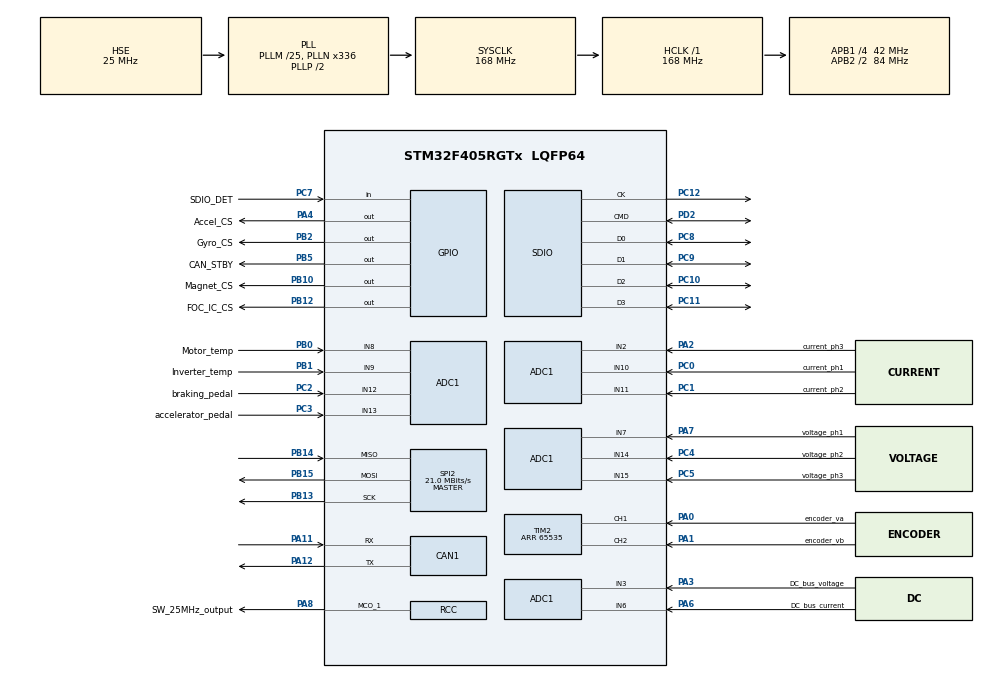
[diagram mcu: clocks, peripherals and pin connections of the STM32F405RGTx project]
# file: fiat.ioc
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ADC1.Channel-10\#ChannelRegularConversion=ADC_CHANNEL_9
ADC1.Channel-11\#ChannelRegularConversion=ADC_CHANNEL_6
ADC1.Channel-12\#ChannelRegularConversion=ADC_CHANNEL_3
ADC1.Channel-13\#ChannelRegularConversion=ADC_CHANNEL_12
ADC1.Channel-14\#ChannelRegularConversion=ADC_CHANNEL_13
ADC1.Channel-3\#ChannelRegularConversion=ADC_CHANNEL_10
ADC1.Channel-4\#ChannelRegularConversion=ADC_CHANNEL_11
ADC1.Channel-5\#ChannelRegularConversion=ADC_CHANNEL_2
ADC1.Channel-6\#ChannelRegularConversion=ADC_CHANNEL_7
ADC1.Channel-7\#ChannelRegularConversion=ADC_CHANNEL_14
ADC1.Channel-8\#ChannelRegularConversion=ADC_CHANNEL_15
ADC1.Channel-9\#ChannelRegularConversion=ADC_CHANNEL_8
ADC1.ContinuousConvMode=ENABLE
ADC1.DMAContinuousRequests=ENABLE
ADC1.NbrOfConversion=12
ADC1.NbrOfConversionFlag=1
ADC1.Rank-10\#ChannelRegularConversion=8
ADC1.Rank-11\#ChannelRegularConversion=9
ADC1.Rank-12\#ChannelRegularConversion=10
ADC1.Rank-13\#ChannelRegularConversion=11
ADC1.Rank-14\#ChannelRegularConversion=12
ADC1.Rank-3\#ChannelRegularConversion=1
ADC1.Rank-4\#ChannelRegularConversion=2
ADC1.Rank-5\#ChannelRegularConversion=3
ADC1.Rank-6\#ChannelRegularConversion=4
ADC1.Rank-7\#ChannelRegularConversion=5
ADC1.Rank-8\#ChannelRegularConversion=6
ADC1.Rank-9\#ChannelRegularConversion=7
ADC1.SamplingTime-10\#ChannelRegularConversion=ADC_SAMPLETIME_3CYCLES
ADC1.SamplingTime-11\#ChannelRegularConversion=ADC_SAMPLETIME_3CYCLES
ADC1.SamplingTime-12\#ChannelRegularConversion=ADC_SAMPLETIME_3CYCLES
ADC1.SamplingTime-13\#ChannelRegularConversion=ADC_SAMPLETIME_3CYCLES
ADC1.SamplingTime-14\#ChannelRegularConversion=ADC_SAMPLETIME_3CYCLES
ADC1.SamplingTime-3\#ChannelRegularConversion=ADC_SAMPLETIME_3CYCLES
ADC1.SamplingTime-4\#ChannelRegularConversion=ADC_SAMPLETIME_3CYCLES
ADC1.SamplingTime-5\#ChannelRegularConversion=ADC_SAMPLETIME_3CYCLES
ADC1.SamplingTime-6\#ChannelRegularConversion=ADC_SAMPLETIME_3CYCLES
ADC1.SamplingTime-7\#ChannelRegularConversion=ADC_SAMPLETIME_3CYCLES
ADC1.SamplingTime-8\#ChannelRegularConversion=ADC_SAMPLETIME_3CYCLES
ADC1.SamplingTime-9\#ChannelRegularConversion=ADC_SAMPLETIME_3CYCLES
ADC1.ScanConvMode=ENABLE
ADC1.master=1
CAN1.CalculateTimeQuantum=380.95238095238096
Dma.ADC1.0.Direction=DMA_PERIPH_TO_MEMORY
Dma.ADC1.0.FIFOMode=DMA_FIFOMODE_DISABLE
Dma.ADC1.0.Instance=DMA2_Stream0
Dma.ADC1.0.MemDataAlignment=DMA_MDATAALIGN_WORD
Dma.ADC1.0.MemInc=DMA_MINC_ENABLE
Dma.ADC1.0.Mode=DMA_CIRCULAR
Dma.ADC1.0.PeriphDataAlignment=DMA_PDATAALIGN_WORD
Dma.ADC1.0.PeriphInc=DMA_PINC_DISABLE
Dma.ADC1.0.Priority=DMA_PRIORITY_LOW
Dma.Request0=ADC1
FATFS.BSP.number=1
FATFS._FS_NORTC=0
FATFS0.BSP.STBoard=false
FATFS0.BSP.api=Unknown
FATFS0.BSP.i2caddr=0
FATFS0.BSP.instance=PC7
FATFS0.BSP.ip=GPIO
FATFS0.BSP.mode=Input
FATFS0.BSP.name=Detect_SDIO
FATFS0.BSP.solution=PC7
Mcu.Family=STM32F4
Mcu.Name=STM32F405RGTx
Mcu.Package=LQFP64
NVIC.DMA2_Stream0_IRQn=true\:0\:0\:false\:false\:true\:false\:true
NVIC.PriorityGroup=NVIC_PRIORITYGROUP_4
NVIC.RTC_Alarm_IRQn=true\:0\:0\:false\:false\:true\:true\:true
NVIC.TIM6_DAC_IRQn=true\:0\:0\:false\:false\:true\:true\:true
PA0-WKUP.GPIO_Label=encoder_va
PA0-WKUP.GPIO_PuPd=GPIO_PULLUP
PA0-WKUP.Signal=S_TIM2_CH1_ETR
PA1.GPIO_Label=encoder_vb
PA1.GPIO_PuPd=GPIO_PULLUP
PA1.Signal=S_TIM2_CH2
PA11.Mode=Master
PA11.Signal=CAN1_RX
PA12.Mode=Master
PA12.Signal=CAN1_TX
PA13.Mode=Serial_Wire
PA13.Signal=SYS_JTMS-SWDIO
PA14.Mode=Serial_Wire
PA14.Signal=SYS_JTCK-SWCLK
PA2.GPIO_Label=current_ph3
PA2.Signal=ADCx_IN2
PA3.GPIO_Label=DC_bus_voltage
PA3.Signal=ADCx_IN3
PA4.GPIO_Label=Accel_CS
PA4.Signal=GPIO_Output
PA6.GPIO_Label=DC_bus_current
PA6.Signal=ADCx_IN6
PA7.GPIO_Label=voltage_ph1
PA7.Signal=ADCx_IN7
PA8.GPIO_Label=SW_25MHz_output
PA8.Mode=Clock-out-1
PA8.Signal=RCC_MCO_1
PB0.GPIO_Label=Motor_temp
PB0.Signal=ADCx_IN8
PB1.GPIO_Label=Inverter_temp
PB1.Signal=ADCx_IN9
PB10.GPIO_Label=Magnet_CS
PB10.Signal=GPIO_Output
PB12.GPIO_Label=FOC_IC_CS
PB12.Signal=GPIO_Output
PB13.Mode=Full_Duplex_Master
PB13.Signal=SPI2_SCK
PB14.Mode=Full_Duplex_Master
PB14.Signal=SPI2_MISO
PB15.Mode=Full_Duplex_Master
PB15.Signal=SPI2_MOSI
PB2.GPIO_Label=Gyro_CS
PB2.Signal=GPIO_Output
PB5.GPIO_Label=CAN_STBY
PB5.Signal=GPIO_Output
PC0.GPIO_Label=current_ph1
PC0.Signal=ADCx_IN10
PC1.GPIO_Label=current_ph2
PC1.Signal=ADCx_IN11
PC10.Mode=SD_4_bits_Wide_bus
PC10.Signal=SDIO_D2
PC11.Mode=SD_4_bits_Wide_bus
PC11.Signal=SDIO_D3
PC12.Mode=SD_4_bits_Wide_bus
PC12.Signal=SDIO_CK
PC14-OSC32_IN.Mode=LSE-External-Oscillator
PC14-OSC32_IN.Signal=RCC_OSC32_IN
PC15-OSC32_OUT.Mode=LSE-External-Oscillator
PC15-OSC32_OUT.Signal=RCC_OSC32_OUT
PC2.GPIO_Label=braking_pedal
PC2.Signal=ADCx_IN12
PC3.GPIO_Label=accelerator_pedal
PC3.Signal=ADCx_IN13
PC4.GPIO_Label=voltage_ph2
PC4.Signal=ADCx_IN14
PC5.GPIO_Label=voltage_ph3
PC5.Signal=ADCx_IN15
PC7.GPIO_Label=SDIO_DET
PC7.Signal=GPIO_Input
PC8.Mode=SD_4_bits_Wide_bus
PC8.Signal=SDIO_D0
PC9.Mode=SD_4_bits_Wide_bus
PC9.Signal=SDIO_D1
PD2.Mode=SD_4_bits_Wide_bus
PD2.Signal=SDIO_CMD
PH0-OSC_IN.Mode=HSE-External-Oscillator
PH0-OSC_IN.Signal=RCC_OSC_IN
PH1-OSC_OUT.Mode=HSE-External-Oscillator
PH1-OSC_OUT.Signal=RCC_OSC_OUT
ProjectManager.HeapSize=0x200
ProjectManager.StackSize=0x400
ProjectManager.TargetToolchain=STM32CubeIDE
RCC.48MHZClocksFreq_Value=48000000
RCC.AHBFreq_Value=168000000
RCC.APB1CLKDivider=RCC_HCLK_DIV4
RCC.APB1Freq_Value=42000000
RCC.APB1TimFreq_Value=84000000
RCC.APB2CLKDivider=RCC_HCLK_DIV2
RCC.APB2Freq_Value=84000000
RCC.APB2TimFreq_Value=168000000
RCC.CortexFreq_Value=168000000
RCC.HCLKFreq_Value=168000000
RCC.HSE_VALUE=25000000
RCC.HSI_VALUE=16000000
RCC.PLLM=25
RCC.PLLN=336
RCC.PLLQ=7
RCC.PLLSourceVirtual=RCC_PLLSOURCE_HSE
RCC.RCC_MCO1Source=RCC_MCO1SOURCE_HSE
RCC.RCC_MCODiv1=RCC_MCODIV_2
RCC.RCC_RTC_Clock_Source=RCC_RTCCLKSOURCE_LSE
RCC.RCC_RTC_Clock_SourceVirtual=RCC_RTCCLKSOURCE_LSE
RCC.SYSCLKFreq_VALUE=168000000
RCC.SYSCLKSource=RCC_SYSCLKSOURCE_PLLCLK
RCC.VCOOutputFreq_Value=336000000
RTC.Alarm=RTC_ALARM_A
RTC.AlarmMaskDateWeekDay=RTC_ALARMMASK_DATEWEEKDAY
RTC.AlarmMaskHours=RTC_ALARMMASK_HOURS
RTC.AlarmMaskMinutes=RTC_ALARMMASK_MINUTES
RTC.AlarmMaskSeconds=RTC_ALARMMASK_SECONDS
RTC.AlarmSubSecondMask=RTC_ALARMSUBSECONDMASK_ALL
RTC.Date=9
RTC.Hours=16
RTC.Hours_A=0
RTC.Minutes_A=0
RTC.Seconds_A=0
RTC.SubSeconds_A=0
RTC.WeekDay=RTC_WEEKDAY_THURSDAY
RTC.Year=20
SH.ADCx_IN10.0=ADC1_IN10,IN10
SH.ADCx_IN11.0=ADC1_IN11,IN11
SH.ADCx_IN12.0=ADC1_IN12,IN12
SH.ADCx_IN13.0=ADC1_IN13,IN13
SH.ADCx_IN14.0=ADC1_IN14,IN14
SH.ADCx_IN15.0=ADC1_IN15,IN15
SH.ADCx_IN2.0=ADC1_IN2,IN2
SH.ADCx_IN3.0=ADC1_IN3,IN3
SH.ADCx_IN6.0=ADC1_IN6,IN6
SH.ADCx_IN7.0=ADC1_IN7,IN7
SH.ADCx_IN8.0=ADC1_IN8,IN8
SH.ADCx_IN9.0=ADC1_IN9,IN9
SH.S_TIM2_CH1_ETR.0=TIM2_CH1,Encoder_Interface
SH.S_TIM2_CH2.0=TIM2_CH2,Encoder_Interface
SPI2.CLKPhase=SPI_PHASE_2EDGE
SPI2.CLKPolarity=SPI_POLARITY_HIGH
SPI2.CalculateBaudRate=21.0 MBits/s
SPI2.Direction=SPI_DIRECTION_2LINES
SPI2.Mode=SPI_MODE_MASTER
SPI2.VirtualType=VM_MASTER
TIM2.EncoderMode=TIM_ENCODERMODE_TI12
TIM2.IC1Filter=10
TIM2.IC2Filter=10
TIM2.Period=65535
TIM6.Period=1000
TIM6.Prescaler=48000
VP_FATFS_VS_SDIO.Mode=SDIO
VP_RTC_VS_RTC_Activate.Mode=RTC_Enabled
VP_RTC_VS_RTC_Alarm_A_Intern.Mode=Alarm A
VP_RTC_VS_RTC_Calendar.Mode=RTC_Calendar
VP_TIM6_VS_ClockSourceINT.Mode=Enable_Timer
board=custom

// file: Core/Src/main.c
/* USER CODE BEGIN Header */
/**
  ******************************************************************************
  * @file           : main.c
  * @brief          : Main program body
  ******************************************************************************
  * @attention
  *
  * <h2><center>&copy; Copyright (c) 2019 STMicroelectronics.
  * All rights reserved.</center></h2>
  *
  * This software component is licensed by ST under BSD 3-Clause license,
  * the "License"; You may not use this file except in compliance with the
  * License. You may obtain a copy of the License at:
  *                        opensource.org/licenses/BSD-3-Clause
  *
  ******************************************************************************
  */
/* USER CODE END Header */

#include "main.h"
#include "adc.h"
#include "can.h"
#include "dma.h"
#include "fatfs.h"
#include "rtc.h"
#include "sdio.h"
#include "spi.h"
#include "tim.h"
#include "gpio.h"

/* USER CODE BEGIN Includes */
#include "string.h"
#include "stdio.h"
#include "sd_wr.h"
#include "IMU_read.h"
#include "adcUnitConversion.h"
#include "encoderMode.h"
#include "FOC_lib.h"
#include "time.h"

/* USER CODE END Includes */

/* USER CODE BEGIN PD */

	#define	NR_ADC_CHANNELS 12 //Nº de channels adc

/* USER CODE END PD */

/* USER CODE BEGIN PV */

	//SD file variables
	FATFS fs;  // file system
	FIL fil[15];  // file
	FRESULT fresult;  // to store the result
	char buffer[512]; // to store data

	UINT br, bw;   // file read/write count

	/* capacity related variables */
	//DWORD fre_clust;
	DWORD total, free_space;

	//IMU accelerometer data
	int accel_data[3];
	//IMU accelerometer data
	int gyro_data[3];

	//ADCs converted values variables
	float dc_current, current_ph1, current_ph2, current_ph3, dc_voltage, voltage_ph1, voltage_ph2, voltage_ph3,  motor_temp, conv_temp, acc_pedal , brk_pedal;

	//String aux
	char str[30], stamp[5];

	//Encoder mode variables
	uint32_t counter1 = 0, counter2 = 0;
	uint32_t tick = 0;
	float speed = 0;

	//RTC
	RTC_TimeTypeDef currentTime;
	RTC_DateTypeDef currentDate;
	uint32_t time_subsec=0;
	uint16_t msec_stamp=0;

/* USER CODE END PV */

void SystemClock_Config(void);

/* USER CODE BEGIN 0 */

uint32_t adc_dma[NR_ADC_CHANNELS], buffer_dma[NR_ADC_CHANNELS];

void HAL_ADC_ConvCpltCallback(ADC_HandleTypeDef* hadc)
{
	for(int i=0; i < NR_ADC_CHANNELS; i++)
	{
		adc_dma[i]=buffer_dma[i];
	}
}

void HAL_RTC_AlarmAEventCallback(RTC_HandleTypeDef *hrtc)
{
	time_subsec=HAL_GetTick();
}

void HAL_TIM_PeriodElapsedCallback(TIM_HandleTypeDef *htim){

	//UNUSED(htim); será preciso?

	//counter2 = __HAL_TIM_GET_COUNTER(&htim2);
	speed = motorSpeed(&counter1, &tick, htim2);

	/* passa a fazer-se aqui?
	sprintf(str, "%f ", speed);
	update_file("encoder_data.txt", str, get_timestamp(&hrtc, &currentTime, &currentDate), stamp, &(fil[12]), &bw); */

}

/* USER CODE END 0 */

int main(void)
{

  /* MCU Configuration--------------------------------------------------------*/

  /* Reset of all peripherals, Initializes the Flash interface and the Systick. */
  HAL_Init();

  /* USER CODE BEGIN Init */

  HAL_GPIO_WritePin(Accel_CS_GPIO_Port, Accel_CS_Pin, SET);
  HAL_GPIO_WritePin(Gyro_CS_GPIO_Port, Gyro_CS_Pin, SET);
  HAL_GPIO_WritePin(Magnet_CS_GPIO_Port, Magnet_CS_Pin, SET);
  HAL_GPIO_WritePin(FOC_IC_CS_GPIO_Port, FOC_IC_CS_Pin, SET);

  /* USER CODE END Init */

  /* Configure the system clock */
  SystemClock_Config();

  /* Initialize all configured peripherals */
  MX_GPIO_Init();
  MX_ADC1_Init();
  MX_CAN1_Init();
  MX_RTC_Init();
  MX_SPI2_Init();
  MX_FATFS_Init();
  MX_DMA_Init();
  MX_SDIO_SD_Init();
  MX_TIM2_Init();
  MX_TIM6_Init();
  /* USER CODE BEGIN 2 */

  //Initialize FOC-IC registers
  //foc_ic_config(&hspi2);

  //HAL_GPIO_WritePin(FOC_IC_CS_GPIO_Port, FOC_IC_CS_Pin, RESET);
  //HAL_SPI_Transmit(&hspi2, /*reg*/ , /*size*/ , 2000);
  //HAL_GPIO_WritePin(FOC_IC_CS_GPIO_Port, FOC_IC_CS_Pin, SET);

  //Initialize IMU
  IMU_config(&hspi2);
  //printf("HELLO\n");
  //Initialize data logger
  if(mount_card (&fs) != FR_OK){
	  printf("ERROR mounting SD Card");
  }

  HAL_ADC_Start_DMA(&hadc1, buffer_dma, NR_ADC_CHANNELS);
  HAL_TIM_Base_Start_IT(&htim6);

  //Initialize encoder mode
  HAL_TIM_Encoder_Start(&htim2, TIM_CHANNEL_ALL);
  tick = HAL_GetTick();
  counter1 = __HAL_TIM_GET_COUNTER(&htim2);

  /* USER CODE END 2 */

  /* Infinite loop */
  while (1)
  {

    /* USER CODE BEGIN 3 */

	  //convert the 3 adc current values from the motor
	  //CURRENT PH1
	  current_ph1 = motorCurrent(adc_dma[0]);
	  msec_stamp=HAL_GetTick()-time_subsec;
	  sprintf(stamp, "%d", msec_stamp);
	  sprintf(str, "%f ", current_ph1);
	  update_file("phase1_current.txt", str, get_timestamp(&hrtc, &currentTime, &currentDate), stamp, &(fil[7]), &bw);

	  //CURRENT PH2
	  current_ph2 = motorCurrent(adc_dma[1]);
	  msec_stamp=HAL_GetTick()-time_subsec;
	  sprintf(stamp, "%d", msec_stamp);
	  sprintf(str, "%f ", current_ph2);
	  update_file("phase2_current.txt", str, get_timestamp(&hrtc, &currentTime, &currentDate), stamp, &(fil[8]), &bw);

	  //CURRENT PH3
	  current_ph3= motorCurrent(adc_dma[2]);
	  msec_stamp=HAL_GetTick()-time_subsec;
	  sprintf(stamp, "%d", msec_stamp);
	  sprintf(str, "%f ", current_ph3);
	  update_file("phase3_current.txt", str, get_timestamp(&hrtc, &currentTime, &currentDate), stamp, &(fil[9]), &bw);

	  //convert the 3 adc voltage values from the motor
	  voltage_ph1 = voltageAC(adc_dma[3]);
	  voltage_ph2 = voltageAC(adc_dma[4]);
	  voltage_ph3 = voltageAC(adc_dma[5]);

	  //MOTOR TEMP
	  motor_temp = motorTemp(adc_dma[6]); //convert adc value for temperature on motor
	  msec_stamp=HAL_GetTick()-time_subsec;
	  sprintf(stamp, "%d", msec_stamp);
	  sprintf(str, "%f ", motor_temp);
	  update_file("Motor_temperature.txt", str, get_timestamp(&hrtc, &currentTime, &currentDate), stamp, &(fil[10]), &bw);

	  //CONV TEMP
	  conv_temp = igbtTemp(adc_dma[7]); //convert adc value for temperature on converter
	  msec_stamp=HAL_GetTick()-time_subsec;
	  sprintf(stamp, "%d", msec_stamp);
	  sprintf(str, "%f ", conv_temp);
	  update_file("Converter_temperature.txt", str, get_timestamp(&hrtc, &currentTime, &currentDate), stamp, &(fil[11]), &bw);

	  //DC CURRENT
	  dc_current = motorCurrent(adc_dma[8]); //convert adc value for current on DC bus
	  msec_stamp=HAL_GetTick()-time_subsec;
	  sprintf(stamp, "%d", msec_stamp);
	  sprintf(str, "%f ", dc_current);
	  update_file("DC_current.txt", str, get_timestamp(&hrtc, &currentTime, &currentDate), stamp, &(fil[6]), &bw);

	  dc_voltage = voltageDC(adc_dma[9]); //convert adc value for voltage on DC bus

	  //BRK pedal
	  brk_pedal = pedalPos(adc_dma[10]); //convert adc value for braking pedal
	  msec_stamp=HAL_GetTick()-time_subsec;
	  sprintf(stamp, "%d", msec_stamp);
	  sprintf(str, "%f ", brk_pedal);
	  update_file("Braking_Pedal.txt", str, get_timestamp(&hrtc, &currentTime, &currentDate), stamp, &(fil[14]), &bw);

	  //THROTTLE
	  acc_pedal = pedalPos(adc_dma[11]); //convert adc value for throttle
	  msec_stamp=HAL_GetTick()-time_subsec;
	  sprintf(stamp, "%d", msec_stamp);
	  sprintf(str, "%f ", acc_pedal);
	  update_file("Accelerator_pedal.txt", str, get_timestamp(&hrtc, &currentTime, &currentDate), stamp, &(fil[13]), &bw);

	  //ENCODER
	  //read and convert adc values for encoder
	  ////counter1 = __HAL_TIM_GET_COUNTER(&htim2);
	  ///HAL_Delay(500);
	  /*if(HAL_GetTick() - tick > 1000L){
		  counter2 = __HAL_TIM_GET_COUNTER(&htim2);
		  speed = motorSpeed(&counter1, counter2, &tick, htim2);
	  }*/

	  msec_stamp=HAL_GetTick()-time_subsec;
	  sprintf(stamp, "%d", msec_stamp);
	  sprintf(str, "%f ", speed);
	  update_file("encoder_data.txt", str, get_timestamp(&hrtc, &currentTime, &currentDate), stamp, &(fil[12]), &bw);

	  //ACCELEROMETER
	  IMU_acc_read(&hspi2, accel_data); //read and convert accelerometer data
	  msec_stamp=HAL_GetTick()-time_subsec;
	  sprintf(stamp, "%d", msec_stamp);
	  sprintf(str, "%d ", accel_data[0]);

	  //Send read data to SD card
	  update_file("accelerometer_data_x.txt", str, get_timestamp(&hrtc, &currentTime, &currentDate), stamp, &(fil[0]), &bw);
	  sprintf(str, "%d ", accel_data[1]);
	  update_file("accelerometer_data_y.txt", str, get_timestamp(&hrtc, &currentTime, &currentDate), stamp, &(fil[1]), &bw);
	  sprintf(str, "%d ", accel_data[2]);
	  update_file("accelerometer_data_z.txt", str, get_timestamp(&hrtc, &currentTime, &currentDate), stamp, &(fil[2]), &bw);

	  //GYROSCOPE
	  IMU_gyro_read(&hspi2, gyro_data); //read and convert gyroscope data
	  msec_stamp=HAL_GetTick()-time_subsec;
	  sprintf(stamp, "%d", msec_stamp);
	  sprintf(str, "%d ", gyro_data[0]);

	  //Send read data to SD card
	  update_file("gyroscope_data_x.txt", str, get_timestamp(&hrtc, &currentTime, &currentDate), stamp, &(fil[3]), &bw);
	  sprintf(str, "%d ", gyro_data[1]);
	  update_file("gyroscope_data_y.txt", str, get_timestamp(&hrtc, &currentTime, &currentDate), stamp, &(fil[4]), &bw);
	  sprintf(str, "%d ", gyro_data[2]);
	  update_file("gyroscope_data_z.txt", str, get_timestamp(&hrtc, &currentTime, &currentDate), stamp, &(fil[5]), &bw);

	  //DEFINIR O QUE FAZER COM VALORES LIDOS

	  //send torque reference to foc ic

	  //read and convert adc value for accelerator potenciometer

	  //after reading pedal value send ref to FOC-IC

	  //save read values on SD card separate files

  }
  /* USER CODE END 3 */
}

void SystemClock_Config(void)
{
  RCC_OscInitTypeDef RCC_OscInitStruct = {0};
  RCC_ClkInitTypeDef RCC_ClkInitStruct = {0};
  RCC_PeriphCLKInitTypeDef PeriphClkInitStruct = {0};

  /** Configure the main internal regulator output voltage
  */
  __HAL_RCC_PWR_CLK_ENABLE();
  __HAL_PWR_VOLTAGESCALING_CONFIG(PWR_REGULATOR_VOLTAGE_SCALE1);
  /** Initializes the CPU, AHB and APB busses clocks
  */
  RCC_OscInitStruct.OscillatorType = RCC_OSCILLATORTYPE_HSE|RCC_OSCILLATORTYPE_LSE;
  RCC_OscInitStruct.HSEState = RCC_HSE_ON;
  RCC_OscInitStruct.LSEState = RCC_LSE_ON;
  RCC_OscInitStruct.PLL.PLLState = RCC_PLL_ON;
  RCC_OscInitStruct.PLL.PLLSource = RCC_PLLSOURCE_HSE;
  RCC_OscInitStruct.PLL.PLLM = 25;
  RCC_OscInitStruct.PLL.PLLN = 336;
  RCC_OscInitStruct.PLL.PLLP = RCC_PLLP_DIV2;
  RCC_OscInitStruct.PLL.PLLQ = 7;
  if (HAL_RCC_OscConfig(&RCC_OscInitStruct) != HAL_OK)
  {
    Error_Handler();
  }
  /** Initializes the CPU, AHB and APB busses clocks
  */
  RCC_ClkInitStruct.ClockType = RCC_CLOCKTYPE_HCLK|RCC_CLOCKTYPE_SYSCLK
                              |RCC_CLOCKTYPE_PCLK1|RCC_CLOCKTYPE_PCLK2;
  RCC_ClkInitStruct.SYSCLKSource = RCC_SYSCLKSOURCE_PLLCLK;
  RCC_ClkInitStruct.AHBCLKDivider = RCC_SYSCLK_DIV1;
  RCC_ClkInitStruct.APB1CLKDivider = RCC_HCLK_DIV4;
  RCC_ClkInitStruct.APB2CLKDivider = RCC_HCLK_DIV2;

  if (HAL_RCC_ClockConfig(&RCC_ClkInitStruct, FLASH_LATENCY_5) != HAL_OK)
  {
    Error_Handler();
  }
  PeriphClkInitStruct.PeriphClockSelection = RCC_PERIPHCLK_RTC;
  PeriphClkInitStruct.RTCClockSelection = RCC_RTCCLKSOURCE_LSE;
  if (HAL_RCCEx_PeriphCLKConfig(&PeriphClkInitStruct) != HAL_OK)
  {
    Error_Handler();
  }
  HAL_RCC_MCOConfig(RCC_MCO1, RCC_MCO1SOURCE_HSE, RCC_MCODIV_2);
}

/* USER CODE BEGIN 4 */
int __io_putchar(int ch){
	ITM_SendChar(ch);
	return ch;
}

int _write(int file, char *ptr, int len){
	int DataIdx;

	for(DataIdx = 0; DataIdx < len; DataIdx++){
		__io_putchar(*ptr++);
	}
	return len;
}

/* USER CODE END 4 */

void Error_Handler(void)
{
}

/************************ (C) COPYRIGHT STMicroelectronics *****END OF FILE****/
